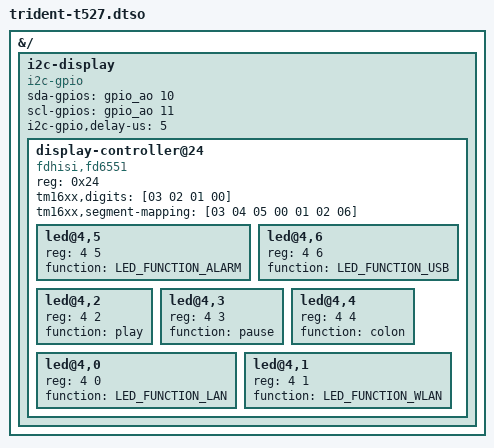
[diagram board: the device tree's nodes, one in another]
/dts-v1/;
/plugin/;

#include <dt-bindings/gpio/gpio.h>
#include <dt-bindings/leds/common.h>

&{/} {

	i2c-display {
		compatible = "i2c-gpio";
		sda-gpios = <&gpio_ao 10 (GPIO_ACTIVE_HIGH | GPIO_OPEN_DRAIN)>;
		scl-gpios = <&gpio_ao 11 (GPIO_ACTIVE_HIGH | GPIO_OPEN_DRAIN)>;
		i2c-gpio,delay-us = <5>;
		#address-cells = <1>;
		#size-cells = <0>;

		display-controller@24 {
			compatible = "fdhisi,fd6551";
			reg = <0x24>;

			tm16xx,digits = [03 02 01 00];
			tm16xx,segment-mapping = [03 04 05 00 01 02 06];

			#address-cells = <2>;
			#size-cells = <0>;
			
			led@4,5 {
				reg = <4 5>;
				function = LED_FUNCTION_ALARM;
			};
			
			led@4,6 {
				reg = <4 6>;
				function = LED_FUNCTION_USB;
			};
			
			led@4,2 {
				reg = <4 2>;
				function = "play";
			};
			
			led@4,3 {
				reg = <4 3>;
				function = "pause";
			};
			
			led@4,4 {
				reg = <4 4>;
				function = "colon";
			};
			
			led@4,0 {
				reg = <4 0>;
				function = LED_FUNCTION_LAN;
			};
			
			led@4,1 {
				reg = <4 1>;
				function = LED_FUNCTION_WLAN;
			};

		};
	};
};

